# cc13x2_cc26x2 register map
File version: 2.1
CPU: CM4 r0p1, little endian, MPU, FPU, 3 interrupt priority bits
Registers are 32-bit, read-write, reset 0x0 unless marked. A register's access mark holds for its fields unless they carry their own. Offsets are from the block's base; [hi:lo] are bit positions; {n}, {i} and the like mark numbered series; <NAME> marks a mode.

## AUX_ANAIF — AUX Analog Interface (AUX_ANAIF) encapsulates direct data and control interfaces between AUX digital and AUX analog circuits. It lets AUX_SCE, UDMA0, and system CPU: Trigger ADC sample and conversion process. Write ADC samples to FIFO. Charge analog nodes by the use of the analog ISRC module. See ADI_4_AUX:ISRC and ADI_4_AUX:COMP.COMPA_REF_CURR_EN for further information. Use the DAC to generate a programmable voltage on COMPB_REF, COMPA_REF, or COMPA_IN analog nodes. o use: ADC : AUX_SCE must request active operational mode with AON_PMCTL:AUXSCECLK.SRC set to SCLK_HFDIV2. There are no requirements for system CPU. ISRC : AUX_SCE must request active operational mode. There are no requirements for system CPU. DAC : AUX_SCE must set AUX_SYSIF:PEROPRATE.ANAIF_DAC_OP_RATE to SCE_RATE as long as DAC state machine generates the sample clock. System CPU must set AUX_SYSIF:PEROPRATE.ANAIF_DAC_OP_RATE to BUS_RATE as long as DAC state machine generates the sample clock. See DACSMPLCTL.EN for further information.
Base 0x400C9000
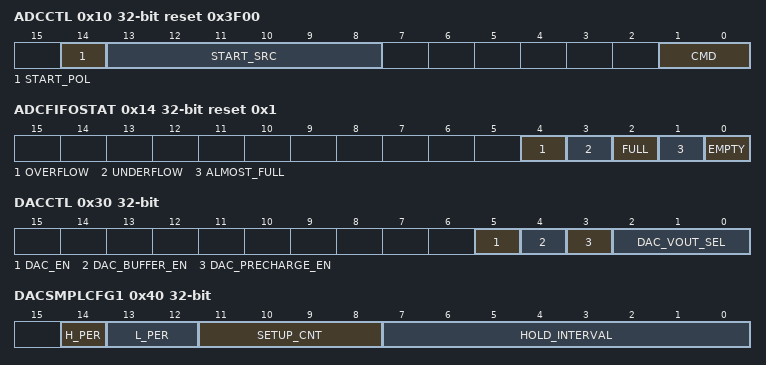
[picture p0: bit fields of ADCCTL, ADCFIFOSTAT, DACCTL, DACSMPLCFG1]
0x10 ADCCTL reset 0x3F00 — ADC Control onfiguration of ADI_4_AUX:ADC0.SMPL_MODE decides if the ADC trigger starts sampling or conversion.
  [14] START_POL, [13:8] START_SRC, [1:0] CMD
0x14 ADCFIFOSTAT ro reset 0x1 — ADC FIFO Status IFO can hold up to four ADC samples.
  [4] OVERFLOW, [3] UNDERFLOW, [2] FULL, [1] ALMOST_FULL, [0] EMPTY
0x18 ADCFIFO
  [11:0] DATA
0x1C ADCTRIG — ADC Trigger
  [0] START
0x20 ISRCCTL reset 0x1 — Current Source Control
  [0] RESET_N
0x30 DACCTL — DAC Control his register controls the analog part of the DAC.
  [5] DAC_EN, [4] DAC_BUFFER_EN, [3] DAC_PRECHARGE_EN, [2:0] DAC_VOUT_SEL
0x34 LPMBIASCTL — Low Power Mode Bias Control he low power mode bias module provides bias current to DAC and Comparator A when AUX_SYSIF:OPMODEREQ.REQ differers from A.
  [0] EN
0x38 DACSMPLCTL — DAC Sample Control he DAC sample clock maintains the DAC voltage stored in the sample-and-hold capacitor. The DAC sample clock waveform consists of a setup phase followed by a hold phase. In the setup phase the sample-and-hold capacitor charges to the programmed voltage. The hold phase maintains the voltage with minimal power. ACSMPLCFG0 and DACSMPLCFG1 configure the DAC sample clock waveform.
  [0] EN
0x3C DACSMPLCFG0 — DAC Sample Configuration 0
  [5:0] CLKDIV
0x40 DACSMPLCFG1 — DAC Sample Configuration 1 he sample clock period equals (high time + low time) * base period. DACSMPLCFG0.CLKDIV determines the base period. iming requirements (DAC Buffer On / DAC Buffer Off): (high time + low time) * base period > (4 us / 1 us) (high time * base period) > (2 us / 0.5 us) (low time * base period) > (2 us / 0.5 us) (low time * base period + HOLD_INTERVAL * sample clock period) < 32 us f AUX_SYSIF:OPMODEREQ.REQ equals PDLP, you must set: H_PER = L_PER = HOLD_INTERVAL = 0.
  [14] H_PER, [13:12] L_PER, [11:8] SETUP_CNT, [7:0] HOLD_INTERVAL
0x44 DACVALUE
  [7:0] VALUE
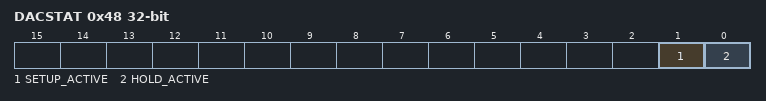
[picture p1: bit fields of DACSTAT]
0x48 DACSTAT ro — DAC Status
  [1] SETUP_ACTIVE, [0] HOLD_ACTIVE

## AUX_MAC — The AUX Multiply-Accumulate (AUX_MAC) peripheral enables AUX_SCE with power-efficient and flexible mathematical operations: 2's complement signed and unsigned sequential multiplication (MUL) with optional accumulation of the result (MAC). 16 or 32-bit 2's complement signed and unsigned addition of configurable term and accumulator (ADD). Results of ADD, MUL and MAC operations are always stored in the accumulator (ACC). oftware can easily: Access arbitrary 16-bit slice of the 40-bit accumulator. Find the number of leading zero or sign bits. Perform shift operations on the accumulator. UX_SCE must set AUX_SYSIF:PEROPRATE.MAC_OP_RATE to SCE_RATE to access and use AUX_MAC. System CPU must set AUX_SYSIF:PEROPRATE.MAC_OP_RATE to BUS_RATE to access and use AUX_MAC. This guarantees constant execution times for ADD, MUL, and MAC operations. he ADD operation requires a single peripheral clock cycle to finish. MUL and MAC operations require four peripheral clock periods to finish. An unfinished ADD, MUL, or MAC operation stalls register access to this peripheral. AUX_SCE becomes clock gated if it encounters a bus stall. Software can use this to reduce power consumption during back to back accesses. nly full word access is supported by the peripheral. An attempt to write a single byte will have no effect.
Base 0x400C2000
0x00 OP0S wo — Signed Operand 0
  [15:0] OP0_VALUE
0x04 OP0U wo — Unsigned Operand 0
  [15:0] OP0_VALUE
0x08 OP1SMUL wo — Signed Operand 1 and Multiply
  [15:0] OP1_VALUE
0x0C OP1UMUL wo — Unsigned Operand 1 and Multiply
  [15:0] OP1_VALUE
0x10 OP1SMAC wo — Signed Operand 1 and Multiply-Accumulate
  [15:0] OP1_VALUE
0x14 OP1UMAC wo — Unsigned Operand 1 and Multiply-Accumulate
  [15:0] OP1_VALUE
0x18 OP1SADD16 wo — Signed Operand 1 and 16-bit Addition
  [15:0] OP1_VALUE
0x1C OP1UADD16 wo — Unsigned Operand 1 and 16-bit Addition
  [15:0] OP1_VALUE
0x20 OP1SADD32 wo — Signed Operand 1 and 32-bit Addition
  [15:0] OP1_VALUE
0x24 OP1UADD32 wo — Unsigned Operand 1 and 32-bit Addition
  [15:0] OP1_VALUE
0x28 CLZ ro reset 0x28 — Count Leading Zero
  [5:0] VALUE
0x2C CLS ro reset 0x28 — Count Leading Sign
  [5:0] VALUE
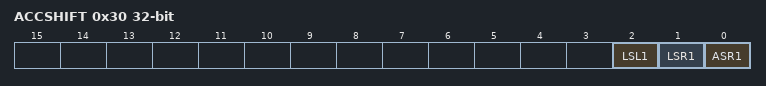
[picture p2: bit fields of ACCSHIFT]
0x30 ACCSHIFT wo — Accumulator Shift nly one shift operation can be triggered per register write.
  [2] LSL1, [1] LSR1, [0] ASR1
0x34 ACCRESET wo — Accumulator Reset
  [15:0] TRG
0x38 ACC15_0 — Accumulator Bits 15:0
  [15:0] VALUE
{0x38+4i} ACC{i+15}_{i} ro (i=1..15) — Accumulator Bits {i+15}:{i}
  [15:0] VALUE
0x78 ACC31_16 — Accumulator Bits 31:16
  [15:0] VALUE
{0x38+4i} ACC{i+15}_{i} ro (i=17..24) — Accumulator Bits {i+15}:{i}
  [15:0] VALUE
0x9C ACC39_32 — Accumulator Bits 39:32
  [7:0] VALUE
